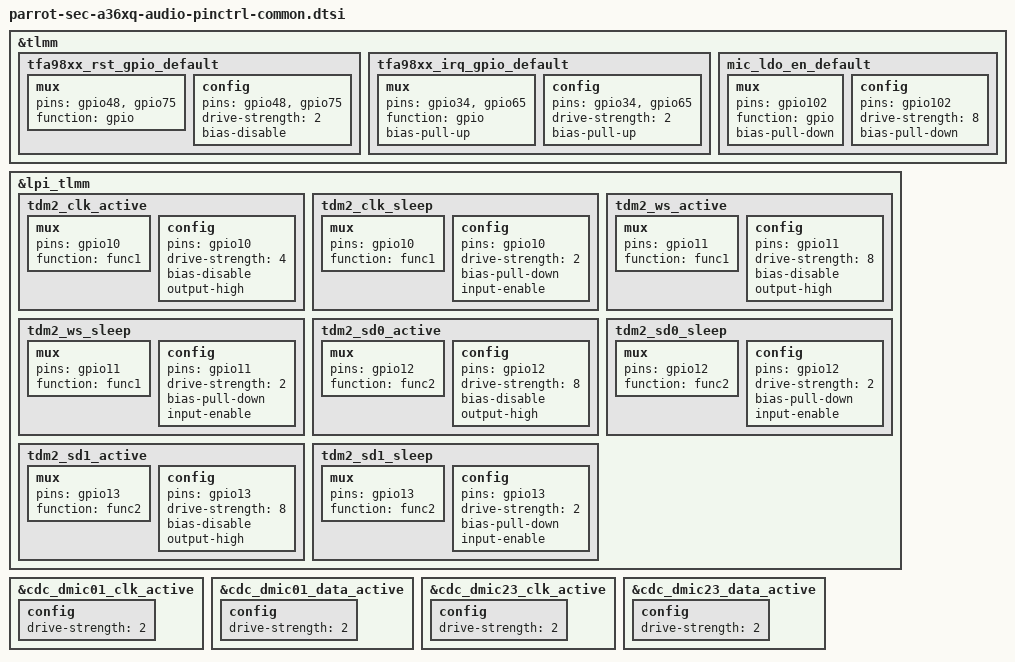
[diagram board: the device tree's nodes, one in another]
// SPDX-License-Identifier: BSD-3-Clause
/*
 * Copyright (c) 2023-2024 Qualcomm Innovation Center, Inc. All rights reserved.
 */

&tlmm {
	tfa98xx_rst_gpio_default: tfa98xx_rst_gpio_default {
		mux {
			pins = "gpio48" , "gpio75";
			function = "gpio";
		};
		config {
			pins = "gpio48" , "gpio75";
			drive-strength = <2>; /* 2 MA */
			bias-disable; /* No PULL */
		};
	};

	tfa98xx_irq_gpio_default: tfa98xx_irq_gpio_default {
		mux {
			pins = "gpio34", "gpio65";
			function = "gpio";
			bias-pull-up;
		};
		config {
			pins = "gpio34", "gpio65";
			drive-strength = <2>; /* 2 MA */
			bias-pull-up;
		};
	};

	mic_ldo_en_default: mic_ldo_en_default {
		mux {
			pins = "gpio102";
			function = "gpio";
			bias-pull-down;
		};
		config {
			pins = "gpio102";
			drive-strength = <8>; /* 8 MA */
			bias-pull-down;
		};
	};
};

&lpi_tlmm {
	tdm2_clk_active: tdm2_clk_active {
		mux {
			pins = "gpio10";
			function = "func1";
		};

		config {
			pins = "gpio10";
			drive-strength = <4>;   /* 4 mA */
			bias-disable;           /* NO PULL */
			output-high;
		};
	};

	tdm2_clk_sleep: tdm2_clk_sleep {
		mux {
			pins = "gpio10";
			function = "func1";
		};

		config {
			pins = "gpio10";
			drive-strength = <2>;   /* 2 mA */
			bias-pull-down;         /* PULL DOWN */
			input-enable;
		};
	};

	tdm2_ws_active: tdm2_ws_active {
		mux {
			pins = "gpio11";
			function = "func1";
		};

		config {
			pins = "gpio11";
			drive-strength = <8>;   /* 8 mA */
			bias-disable;           /* NO PULL */
			output-high;
		};
	};

	tdm2_ws_sleep: tdm2_ws_sleep {
		mux {
			pins = "gpio11";
			function = "func1";
		};

		config {
			pins = "gpio11";
			drive-strength = <2>;   /* 2 mA */
			bias-pull-down;         /* PULL DOWN */
			input-enable;
		};
	};

	tdm2_sd0_active: tdm2_sd0_active {
		mux {
			pins = "gpio12";
			function = "func2";
		};

		config {
			pins = "gpio12";
			drive-strength = <8>;   /* 8 mA */
			bias-disable;           /* NO PULL */
			output-high;
		};
	};

	tdm2_sd0_sleep: tdm2_sd0_sleep {
		mux {
			pins = "gpio12";
			function = "func2";
		};

		config {
			pins = "gpio12";
			drive-strength = <2>;   /* 2 mA */
			bias-pull-down;         /* PULL DOWN */
			input-enable;
		};
	};

	tdm2_sd1_active: tdm2_sd1_active {
		mux {
			pins = "gpio13";
			function = "func2";
		};

		config {
			pins = "gpio13";
			drive-strength = <8>;   /* 8 mA */
			bias-disable;           /* NO PULL */
			output-high;
		};
	};

	tdm2_sd1_sleep: tdm2_sd1_sleep {
		mux {
			pins = "gpio13";
			function = "func2";
		};

		config {
			pins = "gpio13";
			drive-strength = <2>;   /* 2 mA */
			bias-pull-down;         /* PULL DOWN */
			input-enable;
		};
	};
};

&cdc_dmic01_clk_active {
	config {
		drive-strength = <2>;
	};
};

&cdc_dmic01_data_active {
	config {
		drive-strength = <2>;
	};
};

&cdc_dmic23_clk_active {
	config {
		drive-strength = <2>;
	};
};

&cdc_dmic23_data_active {
	config {
		drive-strength = <2>;
	};
};

